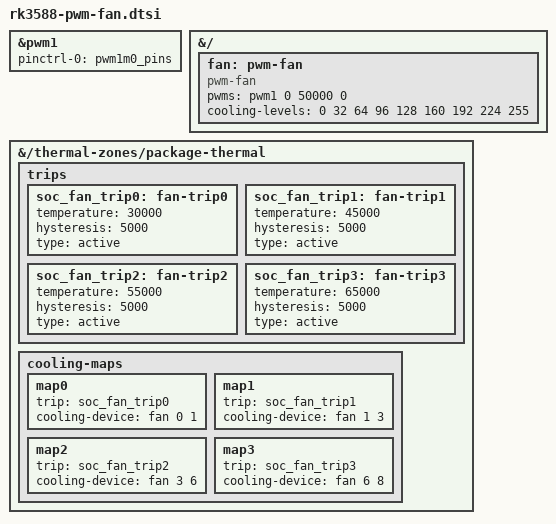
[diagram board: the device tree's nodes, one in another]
&pwm1 {
	pinctrl-0 = <&pwm1m0_pins>;
	pinctrl-names = "default";
	status = "okay";
};

&{/} {
	fan: pwm-fan {
		compatible = "pwm-fan";
		pwms = <&pwm1 0 50000 0>;
		cooling-levels = <0 32 64 96 128 160 192 224 255>;
		#cooling-cells = <2>;
	};
};

// 温控曲线（30°C 起转），绑定到 SoC 封装温度
&{/thermal-zones/package-thermal} {
	trips {
		soc_fan_trip0: fan-trip0 {
			temperature = <30000>;		// 30°C — 起转
			hysteresis = <5000>;
			type = "active";
		};
		soc_fan_trip1: fan-trip1 {
			temperature = <45000>;		// 45°C — 中速
			hysteresis = <5000>;
			type = "active";
		};
		soc_fan_trip2: fan-trip2 {
			temperature = <55000>;		// 55°C — 高速
			hysteresis = <5000>;
			type = "active";
		};
		soc_fan_trip3: fan-trip3 {
			temperature = <65000>;		// 65°C — 全速
			hysteresis = <5000>;
			type = "active";
		};
	};

	cooling-maps {
		map0 {
			trip = <&soc_fan_trip0>;
			cooling-device = <&fan 0 1>;	// 0~32
		};
		map1 {
			trip = <&soc_fan_trip1>;
			cooling-device = <&fan 1 3>;	// 32~96
		};
		map2 {
			trip = <&soc_fan_trip2>;
			cooling-device = <&fan 3 6>;	// 96~192
		};
		map3 {
			trip = <&soc_fan_trip3>;
			cooling-device = <&fan 6 8>;	// 192~255
		};
	};
};
